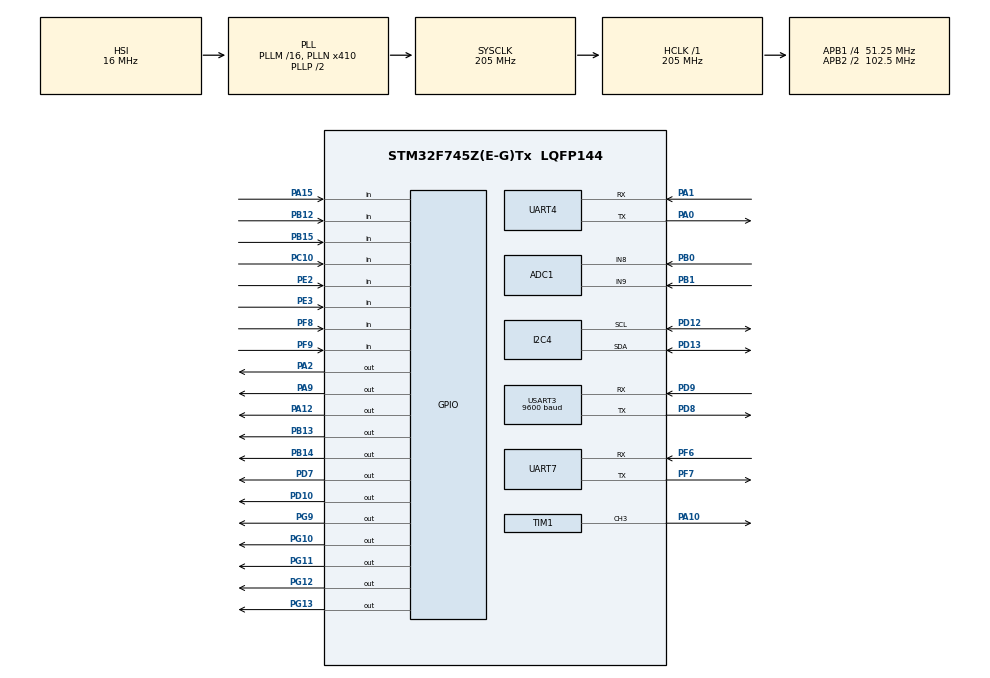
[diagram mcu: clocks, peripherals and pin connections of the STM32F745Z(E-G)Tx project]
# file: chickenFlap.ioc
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ADC1.Channel-2\#ChannelRegularConversion=ADC_CHANNEL_8
ADC1.ClockPrescaler=ADC_CLOCK_SYNC_PCLK_DIV4
ADC1.NbrOfConversionFlag=1
ADC1.Rank-2\#ChannelRegularConversion=1
ADC1.SamplingTime-2\#ChannelRegularConversion=ADC_SAMPLETIME_3CYCLES
ADC1.master=1
I2C4.Timing=0x00C0F6FF
Mcu.Family=STM32F7
Mcu.Name=STM32F745Z(E-G)Tx
Mcu.Package=LQFP144
NVIC.PriorityGroup=NVIC_PRIORITYGROUP_4
PA0/WKUP.Mode=Asynchronous
PA0/WKUP.Signal=UART4_TX
PA1.Mode=Asynchronous
PA1.Signal=UART4_RX
PA10.Signal=S_TIM1_CH3
PA12.Signal=GPIO_Output
PA13.Mode=Serial_Wire
PA13.Signal=SYS_JTMS-SWDIO
PA14.Mode=Serial_Wire
PA14.Signal=SYS_JTCK-SWCLK
PA15.GPIO_PuPd=GPIO_PULLUP
PA15.Signal=GPIO_Input
PA2.Signal=GPIO_Output
PA9.Signal=GPIO_Output
PB0.Signal=ADCx_IN8
PB1.Signal=ADCx_IN9
PB12.GPIO_PuPd=GPIO_PULLUP
PB12.Signal=GPIO_Input
PB13.GPIO_PuPd=GPIO_PULLDOWN
PB13.Signal=GPIO_Output
PB14.Signal=GPIO_Output
PB15.Signal=GPIO_Input
PC10.GPIO_PuPd=GPIO_PULLUP
PC10.Signal=GPIO_Input
PD10.Signal=GPIO_Output
PD12.Mode=I2C
PD12.Signal=I2C4_SCL
PD13.Mode=I2C
PD13.Signal=I2C4_SDA
PD7.GPIO_ModeDefaultOutputPP=GPIO_MODE_OUTPUT_PP
PD7.GPIO_PuPd=GPIO_NOPULL
PD7.Signal=GPIO_Output
PD8.Mode=Asynchronous
PD8.Signal=USART3_TX
PD9.Mode=Asynchronous
PD9.Signal=USART3_RX
PE2.GPIO_PuPd=GPIO_PULLUP
PE2.Signal=GPIO_Input
PE3.GPIO_PuPd=GPIO_PULLUP
PE3.Signal=GPIO_Input
PF6.Mode=Asynchronous
PF6.Signal=UART7_RX
PF7.Mode=Asynchronous
PF7.Signal=UART7_TX
PF8.Signal=GPIO_Input
PF9.GPIO_PuPd=GPIO_PULLUP
PF9.Signal=GPIO_Input
PG10.GPIO_PuPd=GPIO_NOPULL
PG10.Signal=GPIO_Output
PG11.GPIO_PuPd=GPIO_NOPULL
PG11.Signal=GPIO_Output
PG12.GPIO_PuPd=GPIO_NOPULL
PG12.Signal=GPIO_Output
PG13.GPIO_PuPd=GPIO_NOPULL
PG13.Signal=GPIO_Output
PG9.GPIO_PuPd=GPIO_NOPULL
PG9.Signal=GPIO_Output
ProjectManager.HeapSize=0x200
ProjectManager.StackSize=0x400
ProjectManager.TargetToolchain=STM32CubeIDE
RCC.AHBFreq_Value=205000000
RCC.APB1CLKDivider=RCC_HCLK_DIV4
RCC.APB1Freq_Value=51250000
RCC.APB1TimFreq_Value=102500000
RCC.APB2CLKDivider=RCC_HCLK_DIV2
RCC.APB2Freq_Value=102500000
RCC.APB2TimFreq_Value=205000000
RCC.CortexFreq_Value=205000000
RCC.HCLKFreq_Value=205000000
RCC.HSE_VALUE=25000000
RCC.HSI_VALUE=16000000
RCC.LSE_VALUE=32768
RCC.PLLN=410
RCC.SYSCLKFreq_VALUE=205000000
RCC.SYSCLKSource=RCC_SYSCLKSOURCE_PLLCLK
RCC.USBFreq_Value=205000000
RCC.VCOOutputFreq_Value=410000000
SH.ADCx_IN8.0=ADC1_IN8,IN8
SH.ADCx_IN9.0=ADC1_IN9,IN9
SH.S_TIM1_CH3.0=TIM1_CH3,PWM Generation3 CH3
TIM1.Channel-PWM\ Generation3\ CH3=TIM_CHANNEL_3
TIM1.Prescaler=0
USART3.BaudRate=9600
USART3.VirtualMode-Asynchronous=VM_ASYNC
VP_RTC_VS_RTC_Activate.Mode=RTC_Enabled
VP_TIM1_VS_ClockSourceINT.Mode=Internal
board=custom

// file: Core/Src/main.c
/* USER CODE BEGIN Header */
/**
  ******************************************************************************
  * @file           : main.c
  * @brief          : Main program body
  ******************************************************************************
  * @attention
  *
  * Copyright (c) 2023 STMicroelectronics.
  * All rights reserved.
  *
  * This software is licensed under terms that can be found in the LICENSE file
  * in the root directory of this software component.
  * If no LICENSE file comes with this software, it is provided AS-IS.
  *
  ******************************************************************************
  */
/* USER CODE END Header */
#include "main.h"

/* USER CODE BEGIN Includes */
#include "../../chickenFlap/chickenFlap.h"
/* USER CODE END Includes */

ADC_HandleTypeDef hadc1;

I2C_HandleTypeDef hi2c4;

RTC_HandleTypeDef hrtc;

TIM_HandleTypeDef htim1;

UART_HandleTypeDef huart4;
UART_HandleTypeDef huart7;
UART_HandleTypeDef huart3;

void SystemClock_Config(void);
static void MX_GPIO_Init(void);
static void MX_ADC1_Init(void);
static void MX_TIM1_Init(void);
static void MX_UART4_Init(void);
static void MX_USART3_UART_Init(void);
static void MX_I2C4_Init(void);
static void MX_UART7_Init(void);
static void MX_RTC_Init(void);

int main(void)
{

  /* MCU Configuration--------------------------------------------------------*/

  /* Reset of all peripherals, Initializes the Flash interface and the Systick. */
  HAL_Init();

  /* Configure the system clock */
  SystemClock_Config();

  /* Initialize all configured peripherals */
  MX_GPIO_Init();
  MX_ADC1_Init();
  MX_TIM1_Init();
  MX_UART4_Init();
  MX_USART3_UART_Init();
  MX_I2C4_Init();
  MX_UART7_Init();
  MX_RTC_Init();

  /* Infinite loop */
  while (1)
  {

    /* USER CODE BEGIN 3 */
	  chickenFlap_main();
  }
  /* USER CODE END 3 */
}

void SystemClock_Config(void)
{
  RCC_OscInitTypeDef RCC_OscInitStruct = {0};
  RCC_ClkInitTypeDef RCC_ClkInitStruct = {0};

  /** Configure the main internal regulator output voltage
  */
  __HAL_RCC_PWR_CLK_ENABLE();
  __HAL_PWR_VOLTAGESCALING_CONFIG(PWR_REGULATOR_VOLTAGE_SCALE1);

  /** Initializes the RCC Oscillators according to the specified parameters
  * in the RCC_OscInitTypeDef structure.
  */
  RCC_OscInitStruct.OscillatorType = RCC_OSCILLATORTYPE_HSI|RCC_OSCILLATORTYPE_LSI;
  RCC_OscInitStruct.HSIState = RCC_HSI_ON;
  RCC_OscInitStruct.HSICalibrationValue = RCC_HSICALIBRATION_DEFAULT;
  RCC_OscInitStruct.LSIState = RCC_LSI_ON;
  RCC_OscInitStruct.PLL.PLLState = RCC_PLL_ON;
  RCC_OscInitStruct.PLL.PLLSource = RCC_PLLSOURCE_HSI;
  RCC_OscInitStruct.PLL.PLLM = 16;
  RCC_OscInitStruct.PLL.PLLN = 410;
  RCC_OscInitStruct.PLL.PLLP = RCC_PLLP_DIV2;
  RCC_OscInitStruct.PLL.PLLQ = 2;
  if (HAL_RCC_OscConfig(&RCC_OscInitStruct) != HAL_OK)
  {
    Error_Handler();
  }

  /** Activate the Over-Drive mode
  */
  if (HAL_PWREx_EnableOverDrive() != HAL_OK)
  {
    Error_Handler();
  }

  /** Initializes the CPU, AHB and APB buses clocks
  */
  RCC_ClkInitStruct.ClockType = RCC_CLOCKTYPE_HCLK|RCC_CLOCKTYPE_SYSCLK
                              |RCC_CLOCKTYPE_PCLK1|RCC_CLOCKTYPE_PCLK2;
  RCC_ClkInitStruct.SYSCLKSource = RCC_SYSCLKSOURCE_PLLCLK;
  RCC_ClkInitStruct.AHBCLKDivider = RCC_SYSCLK_DIV1;
  RCC_ClkInitStruct.APB1CLKDivider = RCC_HCLK_DIV4;
  RCC_ClkInitStruct.APB2CLKDivider = RCC_HCLK_DIV2;

  if (HAL_RCC_ClockConfig(&RCC_ClkInitStruct, FLASH_LATENCY_6) != HAL_OK)
  {
    Error_Handler();
  }
}

static void MX_ADC1_Init(void)
{

  ADC_ChannelConfTypeDef sConfig = {0};

  /** Configure the global features of the ADC (Clock, Resolution, Data Alignment and number of conversion)
  */
  hadc1.Instance = ADC1;
  hadc1.Init.ClockPrescaler = ADC_CLOCK_SYNC_PCLK_DIV4;
  hadc1.Init.Resolution = ADC_RESOLUTION_12B;
  hadc1.Init.ScanConvMode = ADC_SCAN_DISABLE;
  hadc1.Init.ContinuousConvMode = DISABLE;
  hadc1.Init.DiscontinuousConvMode = DISABLE;
  hadc1.Init.ExternalTrigConvEdge = ADC_EXTERNALTRIGCONVEDGE_NONE;
  hadc1.Init.ExternalTrigConv = ADC_SOFTWARE_START;
  hadc1.Init.DataAlign = ADC_DATAALIGN_RIGHT;
  hadc1.Init.NbrOfConversion = 1;
  hadc1.Init.DMAContinuousRequests = DISABLE;
  hadc1.Init.EOCSelection = ADC_EOC_SINGLE_CONV;
  if (HAL_ADC_Init(&hadc1) != HAL_OK)
  {
    Error_Handler();
  }

  /** Configure for the selected ADC regular channel its corresponding rank in the sequencer and its sample time.
  */
  sConfig.Channel = ADC_CHANNEL_8;
  sConfig.Rank = ADC_REGULAR_RANK_1;
  sConfig.SamplingTime = ADC_SAMPLETIME_3CYCLES;
  if (HAL_ADC_ConfigChannel(&hadc1, &sConfig) != HAL_OK)
  {
    Error_Handler();
  }

}

static void MX_I2C4_Init(void)
{

  hi2c4.Instance = I2C4;
  hi2c4.Init.Timing = 0x00C0F6FF;
  hi2c4.Init.OwnAddress1 = 0;
  hi2c4.Init.AddressingMode = I2C_ADDRESSINGMODE_7BIT;
  hi2c4.Init.DualAddressMode = I2C_DUALADDRESS_DISABLE;
  hi2c4.Init.OwnAddress2 = 0;
  hi2c4.Init.OwnAddress2Masks = I2C_OA2_NOMASK;
  hi2c4.Init.GeneralCallMode = I2C_GENERALCALL_DISABLE;
  hi2c4.Init.NoStretchMode = I2C_NOSTRETCH_DISABLE;
  if (HAL_I2C_Init(&hi2c4) != HAL_OK)
  {
    Error_Handler();
  }

  /** Configure Analogue filter
  */
  if (HAL_I2CEx_ConfigAnalogFilter(&hi2c4, I2C_ANALOGFILTER_ENABLE) != HAL_OK)
  {
    Error_Handler();
  }

  /** Configure Digital filter
  */
  if (HAL_I2CEx_ConfigDigitalFilter(&hi2c4, 0) != HAL_OK)
  {
    Error_Handler();
  }

}

static void MX_RTC_Init(void)
{

  /** Initialize RTC Only
  */
  hrtc.Instance = RTC;
  hrtc.Init.HourFormat = RTC_HOURFORMAT_24;
  hrtc.Init.AsynchPrediv = 127;
  hrtc.Init.SynchPrediv = 255;
  hrtc.Init.OutPut = RTC_OUTPUT_DISABLE;
  hrtc.Init.OutPutPolarity = RTC_OUTPUT_POLARITY_HIGH;
  hrtc.Init.OutPutType = RTC_OUTPUT_TYPE_OPENDRAIN;
  if (HAL_RTC_Init(&hrtc) != HAL_OK)
  {
    Error_Handler();
  }

}

static void MX_TIM1_Init(void)
{

  TIM_ClockConfigTypeDef sClockSourceConfig = {0};
  TIM_MasterConfigTypeDef sMasterConfig = {0};
  TIM_OC_InitTypeDef sConfigOC = {0};
  TIM_BreakDeadTimeConfigTypeDef sBreakDeadTimeConfig = {0};

  htim1.Instance = TIM1;
  htim1.Init.Prescaler = 0;
  htim1.Init.CounterMode = TIM_COUNTERMODE_UP;
  htim1.Init.Period = 65535;
  htim1.Init.ClockDivision = TIM_CLOCKDIVISION_DIV1;
  htim1.Init.RepetitionCounter = 0;
  htim1.Init.AutoReloadPreload = TIM_AUTORELOAD_PRELOAD_DISABLE;
  if (HAL_TIM_Base_Init(&htim1) != HAL_OK)
  {
    Error_Handler();
  }
  sClockSourceConfig.ClockSource = TIM_CLOCKSOURCE_INTERNAL;
  if (HAL_TIM_ConfigClockSource(&htim1, &sClockSourceConfig) != HAL_OK)
  {
    Error_Handler();
  }
  if (HAL_TIM_PWM_Init(&htim1) != HAL_OK)
  {
    Error_Handler();
  }
  sMasterConfig.MasterOutputTrigger = TIM_TRGO_RESET;
  sMasterConfig.MasterOutputTrigger2 = TIM_TRGO2_RESET;
  sMasterConfig.MasterSlaveMode = TIM_MASTERSLAVEMODE_DISABLE;
  if (HAL_TIMEx_MasterConfigSynchronization(&htim1, &sMasterConfig) != HAL_OK)
  {
    Error_Handler();
  }
  sConfigOC.OCMode = TIM_OCMODE_PWM1;
  sConfigOC.Pulse = 0;
  sConfigOC.OCPolarity = TIM_OCPOLARITY_HIGH;
  sConfigOC.OCNPolarity = TIM_OCNPOLARITY_HIGH;
  sConfigOC.OCFastMode = TIM_OCFAST_DISABLE;
  sConfigOC.OCIdleState = TIM_OCIDLESTATE_RESET;
  sConfigOC.OCNIdleState = TIM_OCNIDLESTATE_RESET;
  if (HAL_TIM_PWM_ConfigChannel(&htim1, &sConfigOC, TIM_CHANNEL_3) != HAL_OK)
  {
    Error_Handler();
  }
  sBreakDeadTimeConfig.OffStateRunMode = TIM_OSSR_DISABLE;
  sBreakDeadTimeConfig.OffStateIDLEMode = TIM_OSSI_DISABLE;
  sBreakDeadTimeConfig.LockLevel = TIM_LOCKLEVEL_OFF;
  sBreakDeadTimeConfig.DeadTime = 0;
  sBreakDeadTimeConfig.BreakState = TIM_BREAK_DISABLE;
  sBreakDeadTimeConfig.BreakPolarity = TIM_BREAKPOLARITY_HIGH;
  sBreakDeadTimeConfig.BreakFilter = 0;
  sBreakDeadTimeConfig.Break2State = TIM_BREAK2_DISABLE;
  sBreakDeadTimeConfig.Break2Polarity = TIM_BREAK2POLARITY_HIGH;
  sBreakDeadTimeConfig.Break2Filter = 0;
  sBreakDeadTimeConfig.AutomaticOutput = TIM_AUTOMATICOUTPUT_DISABLE;
  if (HAL_TIMEx_ConfigBreakDeadTime(&htim1, &sBreakDeadTimeConfig) != HAL_OK)
  {
    Error_Handler();
  }
  HAL_TIM_MspPostInit(&htim1);

}

static void MX_UART4_Init(void)
{

  huart4.Instance = UART4;
  huart4.Init.BaudRate = 115200;
  huart4.Init.WordLength = UART_WORDLENGTH_8B;
  huart4.Init.StopBits = UART_STOPBITS_1;
  huart4.Init.Parity = UART_PARITY_NONE;
  huart4.Init.Mode = UART_MODE_TX_RX;
  huart4.Init.HwFlowCtl = UART_HWCONTROL_NONE;
  huart4.Init.OverSampling = UART_OVERSAMPLING_16;
  huart4.Init.OneBitSampling = UART_ONE_BIT_SAMPLE_DISABLE;
  huart4.AdvancedInit.AdvFeatureInit = UART_ADVFEATURE_NO_INIT;
  if (HAL_UART_Init(&huart4) != HAL_OK)
  {
    Error_Handler();
  }

}

static void MX_UART7_Init(void)
{

  huart7.Instance = UART7;
  huart7.Init.BaudRate = 115200;
  huart7.Init.WordLength = UART_WORDLENGTH_8B;
  huart7.Init.StopBits = UART_STOPBITS_1;
  huart7.Init.Parity = UART_PARITY_NONE;
  huart7.Init.Mode = UART_MODE_TX_RX;
  huart7.Init.HwFlowCtl = UART_HWCONTROL_NONE;
  huart7.Init.OverSampling = UART_OVERSAMPLING_16;
  huart7.Init.OneBitSampling = UART_ONE_BIT_SAMPLE_DISABLE;
  huart7.AdvancedInit.AdvFeatureInit = UART_ADVFEATURE_NO_INIT;
  if (HAL_UART_Init(&huart7) != HAL_OK)
  {
    Error_Handler();
  }

}

static void MX_USART3_UART_Init(void)
{

  huart3.Instance = USART3;
  huart3.Init.BaudRate = 9600;
  huart3.Init.WordLength = UART_WORDLENGTH_8B;
  huart3.Init.StopBits = UART_STOPBITS_1;
  huart3.Init.Parity = UART_PARITY_NONE;
  huart3.Init.Mode = UART_MODE_TX_RX;
  huart3.Init.HwFlowCtl = UART_HWCONTROL_NONE;
  huart3.Init.OverSampling = UART_OVERSAMPLING_16;
  huart3.Init.OneBitSampling = UART_ONE_BIT_SAMPLE_DISABLE;
  huart3.AdvancedInit.AdvFeatureInit = UART_ADVFEATURE_NO_INIT;
  if (HAL_UART_Init(&huart3) != HAL_OK)
  {
    Error_Handler();
  }

}

static void MX_GPIO_Init(void)
{
  GPIO_InitTypeDef GPIO_InitStruct = {0};

  /* GPIO Ports Clock Enable */
  __HAL_RCC_GPIOE_CLK_ENABLE();
  __HAL_RCC_GPIOF_CLK_ENABLE();
  __HAL_RCC_GPIOA_CLK_ENABLE();
  __HAL_RCC_GPIOB_CLK_ENABLE();
  __HAL_RCC_GPIOD_CLK_ENABLE();
  __HAL_RCC_GPIOC_CLK_ENABLE();
  __HAL_RCC_GPIOG_CLK_ENABLE();

  /*Configure GPIO pin Output Level */
  HAL_GPIO_WritePin(GPIOA, GPIO_PIN_2|GPIO_PIN_9|GPIO_PIN_12, GPIO_PIN_RESET);

  /*Configure GPIO pin Output Level */
  HAL_GPIO_WritePin(GPIOB, GPIO_PIN_13|GPIO_PIN_14, GPIO_PIN_RESET);

  /*Configure GPIO pin Output Level */
  HAL_GPIO_WritePin(GPIOD, GPIO_PIN_10|GPIO_PIN_7, GPIO_PIN_RESET);

  /*Configure GPIO pin Output Level */
  HAL_GPIO_WritePin(GPIOG, GPIO_PIN_9|GPIO_PIN_10|GPIO_PIN_11|GPIO_PIN_12
                          |GPIO_PIN_13, GPIO_PIN_RESET);

  /*Configure GPIO pins : PE2 PE3 */
  GPIO_InitStruct.Pin = GPIO_PIN_2|GPIO_PIN_3;
  GPIO_InitStruct.Mode = GPIO_MODE_INPUT;
  GPIO_InitStruct.Pull = GPIO_PULLUP;
  HAL_GPIO_Init(GPIOE, &GPIO_InitStruct);

  /*Configure GPIO pin : PF8 */
  GPIO_InitStruct.Pin = GPIO_PIN_8;
  GPIO_InitStruct.Mode = GPIO_MODE_INPUT;
  GPIO_InitStruct.Pull = GPIO_NOPULL;
  HAL_GPIO_Init(GPIOF, &GPIO_InitStruct);

  /*Configure GPIO pin : PF9 */
  GPIO_InitStruct.Pin = GPIO_PIN_9;
  GPIO_InitStruct.Mode = GPIO_MODE_INPUT;
  GPIO_InitStruct.Pull = GPIO_PULLUP;
  HAL_GPIO_Init(GPIOF, &GPIO_InitStruct);

  /*Configure GPIO pins : PA2 PA9 PA12 */
  GPIO_InitStruct.Pin = GPIO_PIN_2|GPIO_PIN_9|GPIO_PIN_12;
  GPIO_InitStruct.Mode = GPIO_MODE_OUTPUT_PP;
  GPIO_InitStruct.Pull = GPIO_NOPULL;
  GPIO_InitStruct.Speed = GPIO_SPEED_FREQ_LOW;
  HAL_GPIO_Init(GPIOA, &GPIO_InitStruct);

  /*Configure GPIO pin : PB12 */
  GPIO_InitStruct.Pin = GPIO_PIN_12;
  GPIO_InitStruct.Mode = GPIO_MODE_INPUT;
  GPIO_InitStruct.Pull = GPIO_PULLUP;
  HAL_GPIO_Init(GPIOB, &GPIO_InitStruct);

  /*Configure GPIO pin : PB13 */
  GPIO_InitStruct.Pin = GPIO_PIN_13;
  GPIO_InitStruct.Mode = GPIO_MODE_OUTPUT_PP;
  GPIO_InitStruct.Pull = GPIO_PULLDOWN;
  GPIO_InitStruct.Speed = GPIO_SPEED_FREQ_LOW;
  HAL_GPIO_Init(GPIOB, &GPIO_InitStruct);

  /*Configure GPIO pin : PB14 */
  GPIO_InitStruct.Pin = GPIO_PIN_14;
  GPIO_InitStruct.Mode = GPIO_MODE_OUTPUT_PP;
  GPIO_InitStruct.Pull = GPIO_NOPULL;
  GPIO_InitStruct.Speed = GPIO_SPEED_FREQ_LOW;
  HAL_GPIO_Init(GPIOB, &GPIO_InitStruct);

  /*Configure GPIO pin : PB15 */
  GPIO_InitStruct.Pin = GPIO_PIN_15;
  GPIO_InitStruct.Mode = GPIO_MODE_INPUT;
  GPIO_InitStruct.Pull = GPIO_NOPULL;
  HAL_GPIO_Init(GPIOB, &GPIO_InitStruct);

  /*Configure GPIO pins : PD10 PD7 */
  GPIO_InitStruct.Pin = GPIO_PIN_10|GPIO_PIN_7;
  GPIO_InitStruct.Mode = GPIO_MODE_OUTPUT_PP;
  GPIO_InitStruct.Pull = GPIO_NOPULL;
  GPIO_InitStruct.Speed = GPIO_SPEED_FREQ_LOW;
  HAL_GPIO_Init(GPIOD, &GPIO_InitStruct);

  /*Configure GPIO pin : PA15 */
  GPIO_InitStruct.Pin = GPIO_PIN_15;
  GPIO_InitStruct.Mode = GPIO_MODE_INPUT;
  GPIO_InitStruct.Pull = GPIO_PULLUP;
  HAL_GPIO_Init(GPIOA, &GPIO_InitStruct);

  /*Configure GPIO pin : PC10 */
  GPIO_InitStruct.Pin = GPIO_PIN_10;
  GPIO_InitStruct.Mode = GPIO_MODE_INPUT;
  GPIO_InitStruct.Pull = GPIO_PULLUP;
  HAL_GPIO_Init(GPIOC, &GPIO_InitStruct);

  /*Configure GPIO pins : PG9 PG10 PG11 PG12
                           PG13 */
  GPIO_InitStruct.Pin = GPIO_PIN_9|GPIO_PIN_10|GPIO_PIN_11|GPIO_PIN_12
                          |GPIO_PIN_13;
  GPIO_InitStruct.Mode = GPIO_MODE_OUTPUT_PP;
  GPIO_InitStruct.Pull = GPIO_NOPULL;
  GPIO_InitStruct.Speed = GPIO_SPEED_FREQ_LOW;
  HAL_GPIO_Init(GPIOG, &GPIO_InitStruct);

}

void Error_Handler(void)
{
  __disable_irq();
  while (1)
  {
  }
}
